# AM335x register map
Vendor: Texas Instruments; Series: Sitara AM335x; File version: 1.1
CPU: Cortex-A8 r0p0, little endian
Registers are 32-bit, read-write, reset 0x0 unless marked. A register's access mark holds for its fields unless they carry their own. Offsets are from the block's base; [hi:lo] are bit positions; 'fields as' and 'values as' point back to an identical list.

## CM_GFX — Clock Module - GFX
Base 0x44E00900
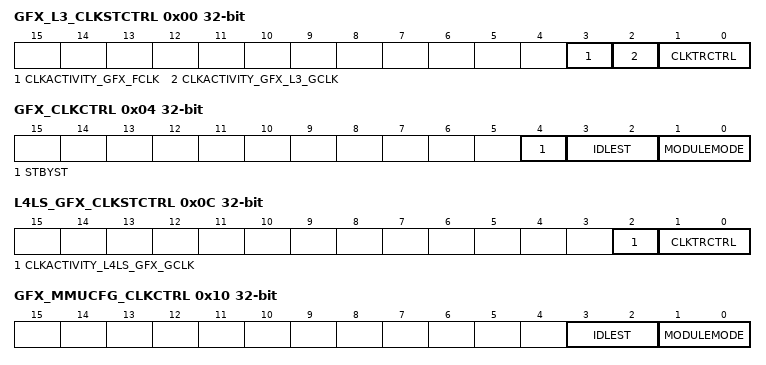
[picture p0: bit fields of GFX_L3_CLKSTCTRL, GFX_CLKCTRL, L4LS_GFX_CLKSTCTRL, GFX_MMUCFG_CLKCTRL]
0x00 GFX_L3_CLKSTCTRL
  [3] CLKACTIVITY_GFX_FCLK — bit: 9 (R)This field indicates the state of the GFX_GCLK clock in the domain. [0x0 = Inact; 0x1 = Act]
  [2] CLKACTIVITY_GFX_L3_GCLK — bit: 8 (R)This field indicates the state of the GFX_L3_GCLK clock in the domain.[0x0 = Inact; 0x1 = Act]
  [1:0] CLKTRCTRL — bit: 0,1 (RW)Clock state transition [see e_PRCM_CLKTRCTRL]
0x04 GFX_CLKCTRL — CM_STBY_CLKCTRL Register
  [4] STBYST — bit: 18 (R)Module standby status.[see e_PRCM_STBYST]
  [3:2] IDLEST — bit: 16,17 (R)Module idle status.[see e_PRCM_IDLEST]
  [1:0] MODULEMODE — bit: 0,1 (RW)Control the way mandatory clocks are managed.[see e_PRCM_MODULEMODE]
0x0C L4LS_GFX_CLKSTCTRL
  [2] CLKACTIVITY_L4LS_GFX_GCLK — bit: 8 (R)This field indicates the state of the L4_LS clock in the domain.[0x0 = Inact; 0x1 = Act]
  [1:0] CLKTRCTRL — bit: 0,1 (RW)Clock state transition [see e_PRCM_CLKTRCTRL]
0x10 GFX_MMUCFG_CLKCTRL — CM_CLKCTRL Register
  [3:2] IDLEST — bit: 16,17 (R)Module idle status.[see e_PRCM_IDLEST]
  [1:0] MODULEMODE — bit: 0,1 (RW)Control the way mandatory clocks are managed.[see e_PRCM_MODULEMODE]
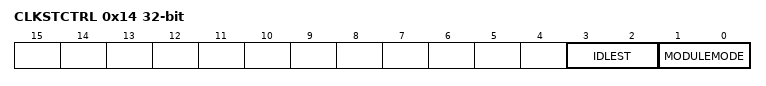
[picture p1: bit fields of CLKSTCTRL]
0x14 CLKSTCTRL — CM_CLKCTRL Register
  fields as GFX_MMUCFG_CLKCTRL

## CM_MPU — Clock Module - MPU
Base 0x44E00600
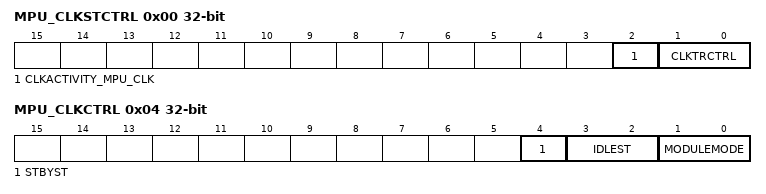
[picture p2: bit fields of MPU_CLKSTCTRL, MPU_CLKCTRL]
0x00 MPU_CLKSTCTRL
  [2] CLKACTIVITY_MPU_CLK — bit: 2 (R)This field indicates the state of the MPU Clock [see e_PRCM_CLK_DOMAIN_ST]
  [1:0] CLKTRCTRL — bit: 0,1 (RW)Clock state transition [see e_PRCM_CLKTRCTRL]
0x04 MPU_CLKCTRL — CM_STBY_CLKCTRL Register
  [4] STBYST — bit: 18 (R)Module standby status.[see e_PRCM_STBYST]
  [3:2] IDLEST — bit: 16,17 (R)Module idle status.[see e_PRCM_IDLEST]
  [1:0] MODULEMODE — bit: 0,1 (RW)Control the way mandatory clocks are managed.[see e_PRCM_MODULEMODE]

## CM_RTC — Clock Module - RTC
Base 0x44E00800
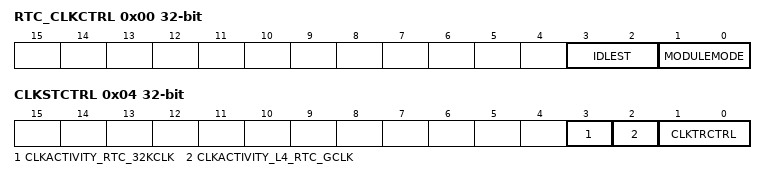
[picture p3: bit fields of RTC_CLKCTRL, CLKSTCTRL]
0x00 RTC_CLKCTRL — CM_CLKCTRL Register
  [3:2] IDLEST — bit: 16,17 (R)Module idle status.[see e_PRCM_IDLEST]
  [1:0] MODULEMODE — bit: 0,1 (RW)Control the way mandatory clocks are managed.[see e_PRCM_MODULEMODE]
0x04 CLKSTCTRL — RTC_CLKSTCTRL Register
  [3] CLKACTIVITY_RTC_32KCLK — bit: 9 (R)This field indicates the state of the 32K RTC clock in the domain [0x0 = Inact; 0x1 = Act]
  [2] CLKACTIVITY_L4_RTC_GCLK — bit: 8 (R)This field indicates the state of the L4 RTC clock in the domain. [0x0 = Inact; 0x1 = Act]
  [1:0] CLKTRCTRL — bit: 0,1 (RW)Clock state transition [see e_PRCM_CLKTRCTRL]

## PRM_CEFUSE — Power Reset Module - CEFUSE
Base 0x44E01200
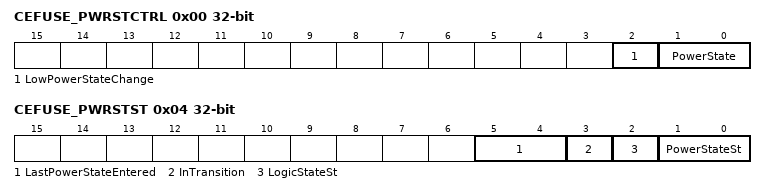
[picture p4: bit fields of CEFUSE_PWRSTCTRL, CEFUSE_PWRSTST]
0x00 CEFUSE_PWRSTCTRL
  [2] LowPowerStateChange — bit: 4 (RW) Power state change request when domain has already performed a sleep transition [0x0 = Do not request; 0x1 = Request a low power state change]
  [1:0] PowerState — bit: 0,1 (RW) Power state control [see e_CEFUSE_PWRSTATE_CTRL]
0x04 CEFUSE_PWRSTST
  [5:4] LastPowerStateEntered — bit: 24,25 (RW)Last low power state entered.Set to 0x3 upon write of the same only. [0x0 = OFF; 0x1 = ON]
  [3] InTransition — bit: 20 (R)Domain transition status [0x0 = No on-going transition; 0x1 = transition is in progress.]
  [2] LogicStateSt — bit: 2 (R)Logic state status [0x0 = logic in domain OFF; 0x1 = logic in domain ON]
  [1:0] PowerStateSt — bit: 0,1 (R)Current Power State Status [see e_CEFUSE_PWRSTST]

## PRM_GFX — Power Reset Module - GFX
Base 0x44E01100
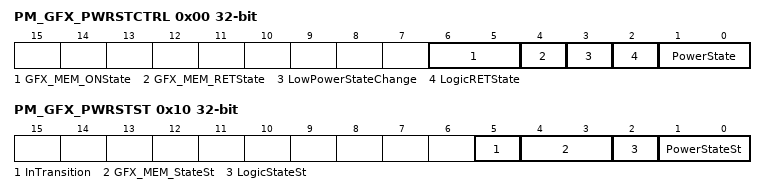
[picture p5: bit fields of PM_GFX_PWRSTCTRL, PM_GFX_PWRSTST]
0x00 PM_GFX_PWRSTCTRL
  [6:5] GFX_MEM_ONState — bit: 17,18 (R) GFX memory state when domain is ON.
  [4] GFX_MEM_RETState — bit: 6 (RW)
  [3] LowPowerStateChange — bit: 4 (RW) Power state change request when domain has already performed a sleep transition [0x0 = Do not request; 0x1 = Request a low power state change]
  [2] LogicRETState — bit: 2 (RW) Logic state when power domain is RETENTION [0x0 = logic_off; 0x1 = logic_ret]
  [1:0] PowerState — bit: 0,1 (RW) Power state control [see e_PWR_STATE_CTRL]
0x04 RM_GFX_RSTCTRL
  [0] GFX_RST — bit: 0 (RW) GFX domain local reset control for (SGX 530) [0x0 = CLEAR; 0x1 = ASSERT]
0x10 PM_GFX_PWRSTST
  [5] InTransition — bit: 20 (R)Domain transition status [0x0 = No on-going transition on power domain; 0x1 = Power domain transition is in progress]
  [4:3] GFX_MEM_StateSt — bit: 4,5 (R)GFX memory state status [see e_GFX_MEMSTST]
  [2] LogicStateSt — bit: 2 (R)Logic state status [0x0 = logic in domain OFF; 0x1 = logic in domain ON]
  [1:0] PowerStateSt — bit: 0,1 (R)Current Power State Status [see e_GFX_PWRSTST]
0x14 RM_GFX_RSTST
  [0] GFX_RST — bit: 0 (RW) GFX Domain Logic Reset [0x0 = RESET_NO; 0x1 = RESET_YES]
